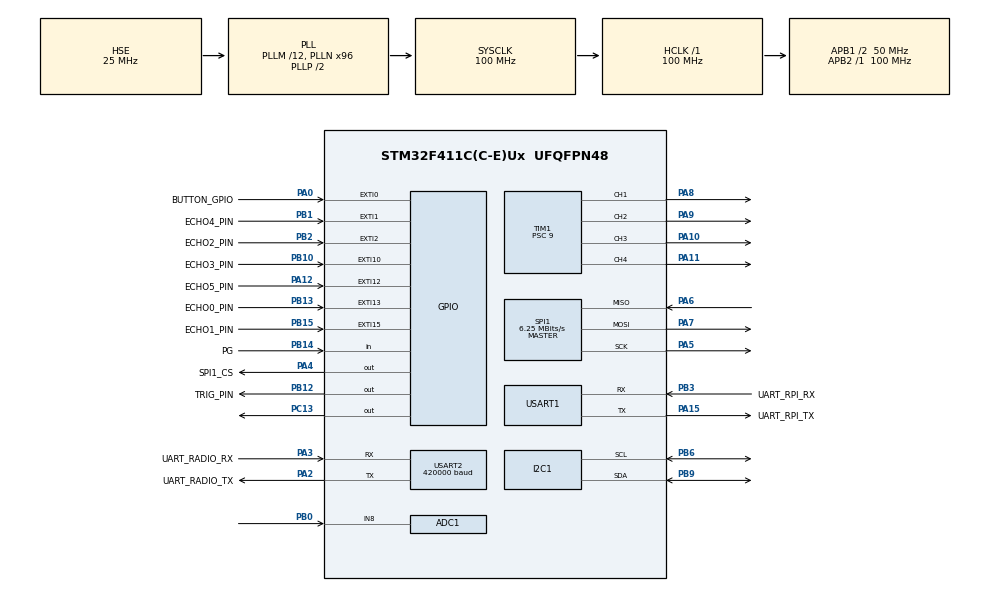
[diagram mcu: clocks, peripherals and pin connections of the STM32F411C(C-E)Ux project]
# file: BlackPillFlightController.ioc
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ADC1.Channel-1\#ChannelRegularConversion=ADC_CHANNEL_8
ADC1.NbrOfConversionFlag=1
ADC1.Rank-1\#ChannelRegularConversion=1
ADC1.SamplingTime-1\#ChannelRegularConversion=ADC_SAMPLETIME_3CYCLES
ADC1.master=1
Dma.I2C1_RX.6.Direction=DMA_PERIPH_TO_MEMORY
Dma.I2C1_RX.6.FIFOMode=DMA_FIFOMODE_DISABLE
Dma.I2C1_RX.6.Instance=DMA1_Stream0
Dma.I2C1_RX.6.MemDataAlignment=DMA_MDATAALIGN_BYTE
Dma.I2C1_RX.6.MemInc=DMA_MINC_ENABLE
Dma.I2C1_RX.6.Mode=DMA_NORMAL
Dma.I2C1_RX.6.PeriphDataAlignment=DMA_PDATAALIGN_BYTE
Dma.I2C1_RX.6.PeriphInc=DMA_PINC_DISABLE
Dma.I2C1_RX.6.Priority=DMA_PRIORITY_HIGH
Dma.Request0=USART1_TX
Dma.Request1=SPI1_RX
Dma.Request2=SPI1_TX
Dma.Request3=USART1_RX
Dma.Request4=USART2_RX
Dma.Request5=TIM1_CH4/TRIG/COM
Dma.Request6=I2C1_RX
Dma.SPI1_RX.1.Direction=DMA_PERIPH_TO_MEMORY
Dma.SPI1_RX.1.FIFOMode=DMA_FIFOMODE_DISABLE
Dma.SPI1_RX.1.Instance=DMA2_Stream0
Dma.SPI1_RX.1.MemDataAlignment=DMA_MDATAALIGN_BYTE
Dma.SPI1_RX.1.MemInc=DMA_MINC_ENABLE
Dma.SPI1_RX.1.Mode=DMA_NORMAL
Dma.SPI1_RX.1.PeriphDataAlignment=DMA_PDATAALIGN_BYTE
Dma.SPI1_RX.1.PeriphInc=DMA_PINC_DISABLE
Dma.SPI1_RX.1.Priority=DMA_PRIORITY_LOW
Dma.SPI1_TX.2.Direction=DMA_MEMORY_TO_PERIPH
Dma.SPI1_TX.2.FIFOMode=DMA_FIFOMODE_DISABLE
Dma.SPI1_TX.2.Instance=DMA2_Stream3
Dma.SPI1_TX.2.MemDataAlignment=DMA_MDATAALIGN_BYTE
Dma.SPI1_TX.2.MemInc=DMA_MINC_ENABLE
Dma.SPI1_TX.2.Mode=DMA_NORMAL
Dma.SPI1_TX.2.PeriphDataAlignment=DMA_PDATAALIGN_BYTE
Dma.SPI1_TX.2.PeriphInc=DMA_PINC_DISABLE
Dma.SPI1_TX.2.Priority=DMA_PRIORITY_LOW
Dma.TIM1_CH4/TRIG/COM.5.Direction=DMA_MEMORY_TO_PERIPH
Dma.TIM1_CH4/TRIG/COM.5.FIFOMode=DMA_FIFOMODE_DISABLE
Dma.TIM1_CH4/TRIG/COM.5.Instance=DMA2_Stream4
Dma.TIM1_CH4/TRIG/COM.5.MemDataAlignment=DMA_MDATAALIGN_HALFWORD
Dma.TIM1_CH4/TRIG/COM.5.MemInc=DMA_MINC_ENABLE
Dma.TIM1_CH4/TRIG/COM.5.Mode=DMA_NORMAL
Dma.TIM1_CH4/TRIG/COM.5.PeriphDataAlignment=DMA_PDATAALIGN_HALFWORD
Dma.TIM1_CH4/TRIG/COM.5.PeriphInc=DMA_PINC_DISABLE
Dma.TIM1_CH4/TRIG/COM.5.Priority=DMA_PRIORITY_HIGH
Dma.USART1_RX.3.Direction=DMA_PERIPH_TO_MEMORY
Dma.USART1_RX.3.FIFOMode=DMA_FIFOMODE_DISABLE
Dma.USART1_RX.3.Instance=DMA2_Stream5
Dma.USART1_RX.3.MemDataAlignment=DMA_MDATAALIGN_BYTE
Dma.USART1_RX.3.MemInc=DMA_MINC_ENABLE
Dma.USART1_RX.3.Mode=DMA_CIRCULAR
Dma.USART1_RX.3.PeriphDataAlignment=DMA_PDATAALIGN_BYTE
Dma.USART1_RX.3.PeriphInc=DMA_PINC_DISABLE
Dma.USART1_RX.3.Priority=DMA_PRIORITY_LOW
Dma.USART1_TX.0.Direction=DMA_MEMORY_TO_PERIPH
Dma.USART1_TX.0.FIFOMode=DMA_FIFOMODE_DISABLE
Dma.USART1_TX.0.Instance=DMA2_Stream7
Dma.USART1_TX.0.MemDataAlignment=DMA_MDATAALIGN_BYTE
Dma.USART1_TX.0.MemInc=DMA_MINC_ENABLE
Dma.USART1_TX.0.Mode=DMA_NORMAL
Dma.USART1_TX.0.PeriphDataAlignment=DMA_PDATAALIGN_BYTE
Dma.USART1_TX.0.PeriphInc=DMA_PINC_DISABLE
Dma.USART1_TX.0.Priority=DMA_PRIORITY_LOW
Dma.USART2_RX.4.Direction=DMA_PERIPH_TO_MEMORY
Dma.USART2_RX.4.FIFOMode=DMA_FIFOMODE_DISABLE
Dma.USART2_RX.4.Instance=DMA1_Stream5
Dma.USART2_RX.4.MemDataAlignment=DMA_MDATAALIGN_BYTE
Dma.USART2_RX.4.MemInc=DMA_MINC_ENABLE
Dma.USART2_RX.4.Mode=DMA_CIRCULAR
Dma.USART2_RX.4.PeriphDataAlignment=DMA_PDATAALIGN_BYTE
Dma.USART2_RX.4.PeriphInc=DMA_PINC_DISABLE
Dma.USART2_RX.4.Priority=DMA_PRIORITY_LOW
FREERTOS.Tasks01=defaultTask,24,128,StartDefaultTask,Default,NULL,Dynamic,NULL,NULL
FREERTOS.configCHECK_FOR_STACK_OVERFLOW=2
FREERTOS.configENABLE_FPU=1
FREERTOS.configGENERATE_RUN_TIME_STATS=1
FREERTOS.configUSE_MALLOC_FAILED_HOOK=1
FREERTOS.configUSE_NEWLIB_REENTRANT=1
FREERTOS.configUSE_STATS_FORMATTING_FUNCTIONS=1
I2C1.I2C_Mode=I2C_Fast
Mcu.Family=STM32F4
Mcu.Name=STM32F411C(C-E)Ux
Mcu.Package=UFQFPN48
NVIC.DMA1_Stream0_IRQn=true\:6\:0\:true\:false\:true\:true\:false\:true\:true
NVIC.DMA1_Stream5_IRQn=true\:7\:0\:true\:false\:true\:true\:false\:true\:true
NVIC.DMA2_Stream0_IRQn=true\:7\:0\:true\:false\:true\:true\:false\:true\:true
NVIC.DMA2_Stream3_IRQn=true\:7\:0\:true\:false\:true\:true\:false\:true\:true
NVIC.DMA2_Stream4_IRQn=true\:6\:0\:true\:false\:true\:true\:false\:true\:true
NVIC.DMA2_Stream5_IRQn=true\:6\:0\:true\:false\:true\:true\:false\:true\:true
NVIC.DMA2_Stream7_IRQn=true\:6\:0\:true\:false\:true\:true\:false\:true\:true
NVIC.EXTI0_IRQn=true\:5\:0\:true\:false\:true\:true\:true\:true\:true
NVIC.EXTI15_10_IRQn=true\:5\:0\:true\:false\:true\:true\:true\:true\:true
NVIC.EXTI1_IRQn=true\:5\:0\:true\:false\:true\:true\:true\:true\:true
NVIC.EXTI2_IRQn=true\:5\:0\:true\:false\:true\:true\:true\:true\:true
NVIC.I2C1_EV_IRQn=true\:6\:0\:true\:false\:true\:true\:true\:true\:true
NVIC.PriorityGroup=NVIC_PRIORITYGROUP_4
NVIC.SPI1_IRQn=true\:7\:0\:true\:false\:true\:true\:true\:true\:true
NVIC.TIM2_IRQn=true\:15\:0\:true\:false\:true\:false\:false\:true\:true
NVIC.TIM3_IRQn=true\:5\:0\:true\:false\:true\:true\:true\:true\:true
NVIC.TIM5_IRQn=true\:6\:0\:true\:false\:true\:true\:true\:true\:true
NVIC.TimeBase=TIM2_IRQn
NVIC.TimeBaseIP=TIM2
NVIC.USART1_IRQn=true\:7\:0\:true\:false\:true\:true\:true\:true\:true
NVIC.USART2_IRQn=true\:7\:0\:true\:false\:true\:true\:true\:true\:true
PA0-WKUP.GPIO_Label=BUTTON_GPIO
PA0-WKUP.GPIO_ModeDefaultEXTI=GPIO_MODE_IT_FALLING
PA0-WKUP.GPIO_PuPd=GPIO_PULLUP
PA0-WKUP.Signal=GPXTI0
PA10.Signal=S_TIM1_CH3
PA11.Signal=S_TIM1_CH4
PA12.GPIO_Label=ECHO5_PIN
PA12.GPIO_ModeDefaultEXTI=GPIO_MODE_IT_RISING_FALLING
PA12.Signal=GPXTI12
PA13.Mode=Serial_Wire
PA13.Signal=SYS_JTMS-SWDIO
PA14.Mode=Serial_Wire
PA14.Signal=SYS_JTCK-SWCLK
PA15.GPIO_Label=UART_RPI_TX
PA15.Mode=Asynchronous
PA15.Signal=USART1_TX
PA2.GPIO_Label=UART_RADIO_TX
PA2.Mode=Asynchronous
PA2.Signal=USART2_TX
PA3.GPIO_Label=UART_RADIO_RX
PA3.Mode=Asynchronous
PA3.Signal=USART2_RX
PA4.GPIO_Label=SPI1_CS
PA4.GPIO_Speed=GPIO_SPEED_FREQ_VERY_HIGH
PA4.PinState=GPIO_PIN_SET
PA4.Signal=GPIO_Output
PA5.Mode=Full_Duplex_Master
PA5.Signal=SPI1_SCK
PA6.Mode=Full_Duplex_Master
PA6.Signal=SPI1_MISO
PA7.Mode=Full_Duplex_Master
PA7.Signal=SPI1_MOSI
PA8.Signal=S_TIM1_CH1
PA9.Signal=S_TIM1_CH2
PB0.Signal=ADCx_IN8
PB1.GPIO_Label=ECHO4_PIN
PB1.GPIO_ModeDefaultEXTI=GPIO_MODE_IT_RISING_FALLING
PB1.Signal=GPXTI1
PB10.GPIO_Label=ECHO3_PIN
PB10.GPIO_ModeDefaultEXTI=GPIO_MODE_IT_RISING_FALLING
PB10.Signal=GPXTI10
PB12.GPIO_Label=TRIG_PIN
PB12.GPIO_ModeDefaultOutputPP=GPIO_MODE_OUTPUT_OD
PB12.GPIO_PuPd=GPIO_NOPULL
PB12.GPIO_Speed=GPIO_SPEED_FREQ_VERY_HIGH
PB12.Signal=GPIO_Output
PB13.GPIO_Label=ECHO0_PIN
PB13.GPIO_ModeDefaultEXTI=GPIO_MODE_IT_RISING_FALLING
PB13.Signal=GPXTI13
PB14.GPIO_Label=PG
PB14.GPIO_PuPd=GPIO_PULLUP
PB14.Signal=GPIO_Input
PB15.GPIO_Label=ECHO1_PIN
PB15.GPIO_ModeDefaultEXTI=GPIO_MODE_IT_RISING_FALLING
PB15.Signal=GPXTI15
PB2.GPIO_Label=ECHO2_PIN
PB2.GPIO_ModeDefaultEXTI=GPIO_MODE_IT_RISING_FALLING
PB2.Signal=GPXTI2
PB3.GPIO_Label=UART_RPI_RX
PB3.Mode=Asynchronous
PB3.Signal=USART1_RX
PB6.Mode=I2C
PB6.Signal=I2C1_SCL
PB7.Signal=S_TIM4_CH2
PB9.Mode=I2C
PB9.Signal=I2C1_SDA
PC13-ANTI_TAMP.Signal=GPIO_Output
PC14-OSC32_IN.Mode=LSE-External-Oscillator
PC14-OSC32_IN.Signal=RCC_OSC32_IN
PC15-OSC32_OUT.Mode=LSE-External-Oscillator
PC15-OSC32_OUT.Signal=RCC_OSC32_OUT
PH0\ -\ OSC_IN.Mode=HSE-External-Oscillator
PH0\ -\ OSC_IN.Signal=RCC_OSC_IN
PH1\ -\ OSC_OUT.Mode=HSE-External-Oscillator
PH1\ -\ OSC_OUT.Signal=RCC_OSC_OUT
ProjectManager.HeapSize=0x200
ProjectManager.StackSize=0x5200
ProjectManager.TargetToolchain=CMake
RCC.48MHZClocksFreq_Value=50000000
RCC.AHBFreq_Value=100000000
RCC.APB1CLKDivider=RCC_HCLK_DIV2
RCC.APB1Freq_Value=50000000
RCC.APB1TimFreq_Value=100000000
RCC.APB2Freq_Value=100000000
RCC.APB2TimFreq_Value=100000000
RCC.CortexFreq_Value=100000000
RCC.HCLKFreq_Value=100000000
RCC.HSE_VALUE=25000000
RCC.HSI_VALUE=16000000
RCC.PLLM=12
RCC.PLLN=96
RCC.PLLSourceVirtual=RCC_PLLSOURCE_HSE
RCC.RCC_RTC_Clock_Source=RCC_RTCCLKSOURCE_LSE
RCC.RCC_RTC_Clock_SourceVirtual=RCC_RTCCLKSOURCE_LSE
RCC.SYSCLKFreq_VALUE=100000000
RCC.SYSCLKSource=RCC_SYSCLKSOURCE_PLLCLK
RCC.VCOOutputFreq_Value=200000000
SH.ADCx_IN8.0=ADC1_IN8,IN8
SH.S_TIM1_CH1.0=TIM1_CH1,PWM Generation1 CH1
SH.S_TIM1_CH2.0=TIM1_CH2,PWM Generation2 CH2
SH.S_TIM1_CH3.0=TIM1_CH3,PWM Generation3 CH3
SH.S_TIM1_CH4.0=TIM1_CH4,PWM Generation4 CH4
SH.S_TIM4_CH2.0=TIM4_CH2
SPI1.BaudRatePrescaler=SPI_BAUDRATEPRESCALER_16
SPI1.CalculateBaudRate=6.25 MBits/s
SPI1.Direction=SPI_DIRECTION_2LINES
SPI1.Mode=SPI_MODE_MASTER
SPI1.VirtualType=VM_MASTER
TIM1.AutoReloadPreload=TIM_AUTORELOAD_PRELOAD_ENABLE
TIM1.Channel-PWM\ Generation1\ CH1=TIM_CHANNEL_1
TIM1.Channel-PWM\ Generation2\ CH2=TIM_CHANNEL_2
TIM1.Channel-PWM\ Generation3\ CH3=TIM_CHANNEL_3
TIM1.Channel-PWM\ Generation4\ CH4=TIM_CHANNEL_4
TIM1.Prescaler=9
TIM3.Channel-Output\ Compare1\ No\ Output=TIM_CHANNEL_1
TIM3.Channel-Output\ Compare2\ No\ Output=TIM_CHANNEL_2
TIM3.Period=65000
TIM3.Prescaler=99
TIM3.TIM_MasterOutputTrigger=TIM_TRGO_OC1REF
TIM4.Channel-Output\ Compare2\ No\ Output=TIM_CHANNEL_2
TIM4.Prescaler=9
TIM4.TIM_MasterOutputTrigger=TIM_TRGO_UPDATE
TIM5.Prescaler=9999
TIM5.TIM_MasterOutputTrigger=TIM_TRGO_UPDATE
USART1.VirtualMode=VM_ASYNC
USART2.BaudRate=420000
USART2.VirtualMode=VM_ASYNC
VP_FREERTOS_VS_CMSIS_V2.Mode=CMSIS_V2
VP_RTC_VS_RTC_Activate.Mode=RTC_Enabled
VP_RTC_VS_RTC_Calendar.Mode=RTC_Calendar
VP_SYS_VS_tim2.Mode=TIM2
VP_TIM1_VS_ClockSourceINT.Mode=Internal
VP_TIM3_VS_ClockSourceINT.Mode=Internal
VP_TIM3_VS_no_output1.Mode=Output Compare1 No Output
VP_TIM3_VS_no_output2.Mode=Output Compare2 No Output
VP_TIM4_VS_ClockSourceINT.Mode=Internal
VP_TIM4_VS_no_output2.Mode=Output Compare2 No Output
VP_TIM5_VS_ClockSourceINT.Mode=Internal
board=custom

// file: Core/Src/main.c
/* USER CODE BEGIN Header */
/**
 ******************************************************************************
 * @file           : main.c
 * @brief          : Main program body
 ******************************************************************************
 * @attention
 *
 * Copyright (c) 2025 STMicroelectronics.
 * All rights reserved.
 *
 * This software is licensed under terms that can be found in the LICENSE file
 * in the root directory of this software component.
 * If no LICENSE file comes with this software, it is provided AS-IS.
 *
 ******************************************************************************
 */
/* USER CODE END Header */
#include "main.h"
#include "cmsis_os.h"
#include "adc.h"
#include "dma.h"
#include "i2c.h"
#include "rtc.h"
#include "spi.h"
#include "tim.h"
#include "usart.h"
#include "gpio.h"

/* USER CODE BEGIN Includes */
#include "Tasks.h"
#include <string.h>
/* USER CODE END Includes */

void SystemClock_Config(void);
void MX_FREERTOS_Init(void);

int main(void)
{

  /* MCU Configuration--------------------------------------------------------*/

  /* Reset of all peripherals, Initializes the Flash interface and the Systick. */
  HAL_Init();

  /* Configure the system clock */
  SystemClock_Config();

  /* Initialize all configured peripherals */
  MX_GPIO_Init();
  MX_DMA_Init();
  MX_USART1_UART_Init();
  MX_I2C1_Init();
  MX_TIM1_Init();
  MX_SPI1_Init();
  MX_TIM3_Init();
  MX_USART2_UART_Init();
  MX_ADC1_Init();
  MX_RTC_Init();
  MX_TIM5_Init();
  MX_TIM4_Init();

  /* Init scheduler */
  osKernelInitialize();  /* Call init function for freertos objects (in cmsis_os2.c) */
  MX_FREERTOS_Init();

  /* Start scheduler */
  osKernelStart();

  /* We should never get here as control is now taken by the scheduler */

  /* Infinite loop */
  while (1) {

  }
}

void SystemClock_Config(void)
{
  RCC_OscInitTypeDef RCC_OscInitStruct = {0};
  RCC_ClkInitTypeDef RCC_ClkInitStruct = {0};

  /** Configure the main internal regulator output voltage
  */
  __HAL_RCC_PWR_CLK_ENABLE();
  __HAL_PWR_VOLTAGESCALING_CONFIG(PWR_REGULATOR_VOLTAGE_SCALE1);

  /** Initializes the RCC Oscillators according to the specified parameters
  * in the RCC_OscInitTypeDef structure.
  */
  RCC_OscInitStruct.OscillatorType = RCC_OSCILLATORTYPE_HSE|RCC_OSCILLATORTYPE_LSE;
  RCC_OscInitStruct.HSEState = RCC_HSE_ON;
  RCC_OscInitStruct.LSEState = RCC_LSE_ON;
  RCC_OscInitStruct.PLL.PLLState = RCC_PLL_ON;
  RCC_OscInitStruct.PLL.PLLSource = RCC_PLLSOURCE_HSE;
  RCC_OscInitStruct.PLL.PLLM = 12;
  RCC_OscInitStruct.PLL.PLLN = 96;
  RCC_OscInitStruct.PLL.PLLP = RCC_PLLP_DIV2;
  RCC_OscInitStruct.PLL.PLLQ = 4;
  if (HAL_RCC_OscConfig(&RCC_OscInitStruct) != HAL_OK)
  {
    Error_Handler();
  }

  /** Initializes the CPU, AHB and APB buses clocks
  */
  RCC_ClkInitStruct.ClockType = RCC_CLOCKTYPE_HCLK|RCC_CLOCKTYPE_SYSCLK
                              |RCC_CLOCKTYPE_PCLK1|RCC_CLOCKTYPE_PCLK2;
  RCC_ClkInitStruct.SYSCLKSource = RCC_SYSCLKSOURCE_PLLCLK;
  RCC_ClkInitStruct.AHBCLKDivider = RCC_SYSCLK_DIV1;
  RCC_ClkInitStruct.APB1CLKDivider = RCC_HCLK_DIV2;
  RCC_ClkInitStruct.APB2CLKDivider = RCC_HCLK_DIV1;

  if (HAL_RCC_ClockConfig(&RCC_ClkInitStruct, FLASH_LATENCY_3) != HAL_OK)
  {
    Error_Handler();
  }
}

void HAL_TIM_PeriodElapsedCallback(TIM_HandleTypeDef *htim)
{
  /* USER CODE BEGIN Callback 0 */
  // if (htim->Instance == TIM3) {
  //   TIM3_TaskNotifyISR();
  // }
  /* USER CODE END Callback 0 */
  if (htim->Instance == TIM2)
  {
    HAL_IncTick();
  }
}

void Error_Handler(void)
{
  /* USER CODE BEGIN Error_Handler_Debug */
  /* User can add his own implementation to report the HAL error return state */
  TaskHandle_t h = xTaskGetCurrentTaskHandle();
  const char *name = pcTaskGetTaskName(h);
  uint8_t buf[100];
  memcpy(buf, "ERR_HANDLER", 12);
  memcpy(buf + 12, name, 80);
  buf[99] = '\0';
  HAL_UART_Transmit(&huart1, buf, sizeof(buf), HAL_MAX_DELAY);
  __disable_irq();
  while (1) {
  }
  /* USER CODE END Error_Handler_Debug */
}
#ifdef USE_FULL_ASSERT
/**
  * @brief  Reports the name of the source file and the source line number
  *         where the assert_param error has occurred.
  * @param  file: pointer to the source file name
  * @param  line: assert_param error line source number
  * @retval None
  */
void assert_failed(uint8_t *file, uint32_t line)
{
  /* USER CODE BEGIN 6 */
  /* User can add his own implementation to report the file name and line
     number, ex: printf("Wrong parameters value: file %s on line %d\r\n", file,
     line) */
  /* USER CODE END 6 */
}
#endif /* USE_FULL_ASSERT */

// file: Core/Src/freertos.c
/* USER CODE BEGIN Header */
/**
 ******************************************************************************
 * File Name          : freertos.c
 * Description        : Code for freertos applications
 ******************************************************************************
 * @attention
 *
 * Copyright (c) 2025 STMicroelectronics.
 * All rights reserved.
 *
 * This software is licensed under terms that can be found in the LICENSE file
 * in the root directory of this software component.
 * If no LICENSE file comes with this software, it is provided AS-IS.
 *
 ******************************************************************************
 */
/* USER CODE END Header */

#include "FreeRTOS.h"
#include "task.h"
#include "main.h"
#include "cmsis_os.h"

/* USER CODE BEGIN Includes */

#include "Program.h"

/* USER CODE END Includes */

/* Definitions for defaultTask */
osThreadId_t defaultTaskHandle;
const osThreadAttr_t defaultTask_attributes = {
  .name = "defaultTask",
  .stack_size = 128 * 4,
  .priority = (osPriority_t) osPriorityNormal,
};

void StartDefaultTask(void *argument);

void MX_FREERTOS_Init(void); /* (MISRA C 2004 rule 8.1) */

/* Hook prototypes */
void configureTimerForRunTimeStats(void);
unsigned long getRunTimeCounterValue(void);

/* USER CODE BEGIN 1 */

/* Functions needed when configGENERATE_RUN_TIME_STATS is on */
__weak void configureTimerForRunTimeStats(void) {}

__weak unsigned long getRunTimeCounterValue(void) { return TIM2->CNT; }
/* USER CODE END 1 */

void MX_FREERTOS_Init(void) {
  /* USER CODE BEGIN Init */
  Init();
  /* USER CODE END Init */

  /* Create the thread(s) */
  /* creation of defaultTask */
  defaultTaskHandle = osThreadNew(StartDefaultTask, NULL, &defaultTask_attributes);

}

void StartDefaultTask(void *argument)
{
  /* USER CODE BEGIN StartDefaultTask */
  for (;;) {
    vTaskSuspend(defaultTaskHandle);
  }
  /* USER CODE END StartDefaultTask */
}
